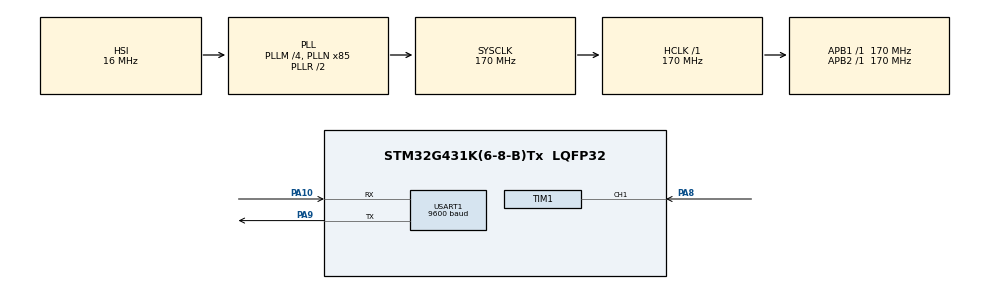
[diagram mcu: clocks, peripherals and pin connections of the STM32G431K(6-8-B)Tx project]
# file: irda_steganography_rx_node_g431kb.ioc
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CRC.CRCLength=CRC_POLYLENGTH_16B
CRC.DefaultInitValueUse=DEFAULT_INIT_VALUE_DISABLE
CRC.DefaultPolynomialUse=DEFAULT_POLYNOMIAL_DISABLE
CRC.GeneratingPolynomial=X12+X5+X0
CRC.InitValue=0xFFFF
CRC.InputDataInversionMode=CRC_INPUTDATA_INVERSION_BYTE
Mcu.Family=STM32G4
Mcu.Name=STM32G431K(6-8-B)Tx
Mcu.Package=LQFP32
NUCLEO-G431KB.Bsp_Common_DEMO=true
NUCLEO-G431KB.VCP=true
NVIC.PriorityGroup=NVIC_PRIORITYGROUP_4
NVIC.TIM1_CC_IRQn=true\:0\:0\:false\:false\:true\:true\:true\:true
NVIC.USART1_IRQn=true\:1\:0\:true\:false\:true\:true\:true\:true
PA10.GPIO_PuPd=GPIO_PULLUP
PA10.Mode=IrDA
PA10.Signal=USART1_RX
PA13.GPIO_Label=T_SWDIO
PA13.Signal=SYS_JTMS-SWDIO
PA14.GPIO_Label=T_SWCLK
PA14.Signal=SYS_JTCK-SWCLK
PA2.Signal=USART2_TX
PA3.Signal=USART2_RX
PA8.Signal=S_TIM1_CH1
PA9.GPIO_PuPd=GPIO_PULLUP
PA9.Mode=IrDA
PA9.Signal=USART1_TX
PB3.GPIO_Label=T_SWO
PB3.Signal=SYS_JTDO-SWO
ProjectManager.HeapSize=0x200
ProjectManager.StackSize=0x400
ProjectManager.TargetToolchain=CMake
RCC.ADC12Freq_Value=170000000
RCC.AHBFreq_Value=170000000
RCC.APB1Freq_Value=170000000
RCC.APB1TimFreq_Value=170000000
RCC.APB2Freq_Value=170000000
RCC.APB2TimFreq_Value=170000000
RCC.CortexFreq_Value=170000000
RCC.EXTERNAL_CLOCK_VALUE=12288000
RCC.HCLKFreq_Value=170000000
RCC.HSE_VALUE=8000000
RCC.HSI48_VALUE=48000000
RCC.HSI_VALUE=16000000
RCC.LSE_VALUE=32768
RCC.PLLM=RCC_PLLM_DIV4
RCC.PLLN=85
RCC.SYSCLKFreq_VALUE=170000000
RCC.SYSCLKSource=RCC_SYSCLKSOURCE_PLLCLK
RCC.USBFreq_Value=170000000
RCC.VCOOutputFreq_Value=340000000
SH.S_TIM1_CH1.0=TIM1_CH1,Input_Capture1_from_TI1
SH.S_TIM1_CH1.1=TIM1_CH1,TriggerSource_TI1ED
TIM1.Channel-Input_Capture1_from_TI1=TIM_CHANNEL_1
USART1.BaudRate=9600
USART1.ClockPrescaler=PRESCALER_DIV1
USART1.VirtualMode-IrDA=VM_IRDA
VP_CRC_VS_CRC.Mode=CRC_Activate
VP_NUCLEO-G431KB_VS_BSP_COMMON.Mode=COMMON
VP_SYS_VS_DBSignals.Mode=DisableDeadBatterySignals
VP_TIM1_VS_ClockSourceINT.Mode=Internal
VP_TIM1_VS_ControllerModeReset.Mode=Reset Mode
board=NUCLEO-G431KB

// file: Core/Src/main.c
/* USER CODE BEGIN Header */
/**
 ******************************************************************************
 * @file           : main.c
 * @brief          : Main program body
 ******************************************************************************
 * @attention
 *
 * Copyright (c) 2026 STMicroelectronics.
 * All rights reserved.
 *
 * This software is licensed under terms that can be found in the LICENSE file
 * in the root directory of this software component.
 * If no LICENSE file comes with this software, it is provided AS-IS.
 *
 ******************************************************************************
 */
/* USER CODE END Header */
#include "main.h"
#include "crc.h"
#include "gpio.h"
#include "tim.h"
#include "usart.h"
#include <string.h>

/* USER CODE BEGIN PTD */

typedef enum {
  PULSE_SHORT = 0,
  PULSE_LONG = 1,
  PULSE_ERROR,
} pulse_t;

/* USER CODE END PTD */

/* USER CODE BEGIN PD */

#define IRDA_PAYLOAD_SIZE 64
#define IRDA_CRC_XOR_VALUE 0xFFFF
#define CRC_HEX_LENGTH 4 // 16-bit CRC

#define STEGANO_PAYLOAD_SIZE 128

/* USER CODE END PD */

COM_InitTypeDef BspCOMInit;

/* USER CODE BEGIN PV */

uint8_t irda_rx_data[IRDA_PAYLOAD_SIZE];
uint8_t irda_rx_byte;
uint8_t irda_data_idx = 0;
uint32_t tic_time;
uint32_t toc_time;
uint16_t msg_str_crc;

uint8_t stegano_data[STEGANO_PAYLOAD_SIZE];
uint16_t stegano_data_idx;

char hidden_msg[STEGANO_PAYLOAD_SIZE];

uint8_t end_delimiter;
uint8_t potential_begin_found = 0;
uint8_t true_begin_found;

uint16_t byte_idx = 0;
uint8_t bit_idx = 0;

/* USER CODE END PV */

void SystemClock_Config(void);
/* USER CODE BEGIN PFP */

pulse_t calc_pulse(uint16_t _time);

/* USER CODE END PFP */

int main(void) {

  /* MCU Configuration--------------------------------------------------------*/

  /* Reset of all peripherals, Initializes the Flash interface and the Systick.
   */
  HAL_Init();

  /* Configure the system clock */
  SystemClock_Config();

  /* Initialize all configured peripherals */
  MX_GPIO_Init();
  MX_USART1_IRDA_Init();
  MX_CRC_Init();
  MX_TIM1_Init();
  /* USER CODE BEGIN 2 */

  HAL_IRDA_Receive_IT(&hirda1, &irda_rx_byte, 1);
  HAL_TIM_IC_Start_IT(&htim1, TIM_CHANNEL_1);

  /* USER CODE END 2 */

  /* Initialize COM1 port (115200, 8 bits (7-bit data + 1 stop bit), no parity
   */
  BspCOMInit.BaudRate = 115200;
  BspCOMInit.WordLength = COM_WORDLENGTH_8B;
  BspCOMInit.StopBits = COM_STOPBITS_1;
  BspCOMInit.Parity = COM_PARITY_NONE;
  BspCOMInit.HwFlowCtl = COM_HWCONTROL_NONE;
  if (BSP_COM_Init(COM1, &BspCOMInit) != BSP_ERROR_NONE) {
    Error_Handler();
  }

  /* USER CODE BEGIN BSP */

  /* -- Sample board code to send message over COM1 port ---- */
  printf("\r\nWelcome to STM32 IrDA steganography world!\r\n");

  /* USER CODE END BSP */

  /* Infinite loop */
  /* USER CODE BEGIN WHILE */
  while (1) {

    __NOP();
    /* USER CODE END WHILE */

  }
}

void SystemClock_Config(void) {
  RCC_OscInitTypeDef RCC_OscInitStruct = {0};
  RCC_ClkInitTypeDef RCC_ClkInitStruct = {0};

  /** Configure the main internal regulator output voltage
   */
  HAL_PWREx_ControlVoltageScaling(PWR_REGULATOR_VOLTAGE_SCALE1_BOOST);

  /** Initializes the RCC Oscillators according to the specified parameters
   * in the RCC_OscInitTypeDef structure.
   */
  RCC_OscInitStruct.OscillatorType = RCC_OSCILLATORTYPE_HSI;
  RCC_OscInitStruct.HSIState = RCC_HSI_ON;
  RCC_OscInitStruct.HSICalibrationValue = RCC_HSICALIBRATION_DEFAULT;
  RCC_OscInitStruct.PLL.PLLState = RCC_PLL_ON;
  RCC_OscInitStruct.PLL.PLLSource = RCC_PLLSOURCE_HSI;
  RCC_OscInitStruct.PLL.PLLM = RCC_PLLM_DIV4;
  RCC_OscInitStruct.PLL.PLLN = 85;
  RCC_OscInitStruct.PLL.PLLP = RCC_PLLP_DIV2;
  RCC_OscInitStruct.PLL.PLLQ = RCC_PLLQ_DIV2;
  RCC_OscInitStruct.PLL.PLLR = RCC_PLLR_DIV2;
  if (HAL_RCC_OscConfig(&RCC_OscInitStruct) != HAL_OK) {
    Error_Handler();
  }

  /** Initializes the CPU, AHB and APB buses clocks
   */
  RCC_ClkInitStruct.ClockType = RCC_CLOCKTYPE_HCLK | RCC_CLOCKTYPE_SYSCLK |
                                RCC_CLOCKTYPE_PCLK1 | RCC_CLOCKTYPE_PCLK2;
  RCC_ClkInitStruct.SYSCLKSource = RCC_SYSCLKSOURCE_PLLCLK;
  RCC_ClkInitStruct.AHBCLKDivider = RCC_SYSCLK_DIV1;
  RCC_ClkInitStruct.APB1CLKDivider = RCC_HCLK_DIV1;
  RCC_ClkInitStruct.APB2CLKDivider = RCC_HCLK_DIV1;

  if (HAL_RCC_ClockConfig(&RCC_ClkInitStruct, FLASH_LATENCY_4) != HAL_OK) {
    Error_Handler();
  }
}

/* USER CODE BEGIN 4 */

pulse_t calc_pulse(uint16_t _time) {
  if (_time < 15 * 170) // @170 MHz
    return PULSE_ERROR;
  else if (_time < 25 * 170)
    return PULSE_SHORT;
  else if (_time < 35 * 170)
    return PULSE_LONG;
  else
    return PULSE_ERROR;
}

void HAL_TIM_IC_CaptureCallback(TIM_HandleTypeDef *htim) {
  pulse_t _new_val;
  if ((htim->Instance == TIM1) && (htim->Channel == HAL_TIM_ACTIVE_CHANNEL_1)) {
    _new_val = calc_pulse(HAL_TIM_ReadCapturedValue(htim, TIM_CHANNEL_1));

    if (potential_begin_found == 1) {
      if (_new_val == PULSE_LONG) {
        true_begin_found = 1;
        potential_begin_found = 0;
      }
    }

    if (true_begin_found && (byte_idx < STEGANO_PAYLOAD_SIZE)) {
      if (_new_val == PULSE_LONG) {
        stegano_data[byte_idx] |= (1 << bit_idx);
      }
      bit_idx++;
      if (bit_idx == 8) {
        bit_idx = 0;
        byte_idx++;
      }
    }

    if (_new_val == PULSE_SHORT) {
      end_delimiter++;
    } else {
      end_delimiter = 0;
    }
    if (end_delimiter == 16) {
      potential_begin_found = 1;
      true_begin_found = 0;
      end_delimiter = 0;
      byte_idx = 0;
      bit_idx = 0;
      sprintf(hidden_msg, "\r\nHidden message: %s\r\n\r\n\r\n",
              (char *)(stegano_data + 1));
      memset(stegano_data, 0x00, STEGANO_PAYLOAD_SIZE);
    }
  }
}

void HAL_IRDA_RxCpltCallback(IRDA_HandleTypeDef *hirda) {
  if (hirda->Instance == USART1) {

    if (irda_data_idx < IRDA_PAYLOAD_SIZE) {
      irda_rx_data[irda_data_idx] = irda_rx_byte;
      HAL_IRDA_Receive_IT(&hirda1, &irda_rx_byte, 1);

      if (irda_rx_byte != '\0') {
        irda_data_idx++;
      } else if (irda_data_idx >= CRC_HEX_LENGTH) {
        toc_time = HAL_GetTick();
        msg_str_crc = HAL_CRC_Calculate(&hcrc, (uint32_t *)irda_rx_data,
                                        irda_data_idx - CRC_HEX_LENGTH) ^
                      IRDA_CRC_XOR_VALUE;
        uint32_t crc_appended;
        sscanf((char *)irda_rx_data + irda_data_idx - CRC_HEX_LENGTH, "%4X",
               (unsigned int *)(&crc_appended));

        printf("Raw string: %s\r\n", irda_rx_data);
        printf("CRC_TX: 0x%04X\r\n", (unsigned int)crc_appended);
        printf("CRC_RX: 0x%04X (%s)\r\n", (unsigned int)msg_str_crc,
               msg_str_crc == crc_appended ? "OK" : "ERROR");
        *(irda_rx_data + irda_data_idx - CRC_HEX_LENGTH) = '\0';
        if (msg_str_crc == crc_appended) {
          printf("Message: %s\r\n", irda_rx_data);
        }
        printf("Time passed: %lu ms\r\n\r\n", toc_time - tic_time);
        printf("%s", hidden_msg);
        irda_data_idx = 0;
        tic_time = toc_time;
      } else {
        irda_data_idx = 0;
        HAL_IRDA_Receive_IT(&hirda1, &irda_rx_byte, 1);
      }
    } else {
      irda_data_idx = 0;
      HAL_IRDA_Receive_IT(&hirda1, &irda_rx_byte, 1);
    }
  }
}

/* USER CODE END 4 */

/* USER CODE BEGIN Header */
/**
 ******************************************************************************
 * @file           : main.c
 * @brief          : Main program body
 ******************************************************************************
 * @attention
 *
 * Copyright (c) 2026 STMicroelectronics.
 * All rights reserved.
 *
 * This software is licensed under terms that can be found in the LICENSE file
 * in the root directory of this software component.
 * If no LICENSE file comes with this software, it is provided AS-IS.
 *
 ******************************************************************************
 */
/* USER CODE END Header */

void Error_Handler(void) {
  __disable_irq();
  while (1) {
  }
}
#ifdef USE_FULL_ASSERT
/**
 * @brief  Reports the name of the source file and the source line number
 *         where the assert_param error has occurred.
 * @param  file: pointer to the source file name
 * @param  line: assert_param error line source number
 * @retval None
 */
void assert_failed(uint8_t *file, uint32_t line) {
  /* USER CODE BEGIN 6 */
  /* User can add his own implementation to report the file name and line
     number, ex: printf("Wrong parameters value: file %s on line %d\r\n", file,
     line) */
  /* USER CODE END 6 */
}
#endif /* USE_FULL_ASSERT */
